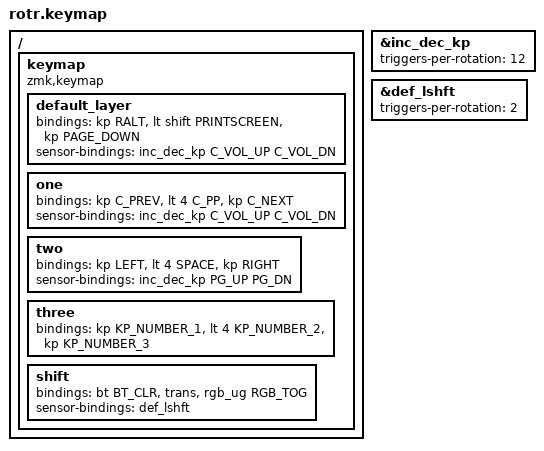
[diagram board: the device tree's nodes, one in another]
#include <behaviors.dtsi>
#include <dt-bindings/zmk/keys.h>
#include <dt-bindings/zmk/rgb.h>
#include <dt-bindings/zmk/bt.h>

&inc_dec_kp {
	triggers-per-rotation = <12>;
};
&def_lshft {
	triggers-per-rotation = <2>;
};

/ {
	keymap {
		compatible = "zmk,keymap";

		default_layer {
			//FUNCTION MACROS
			bindings = <&kp RALT &lt shift PRINTSCREEN &kp PAGE_DOWN>;
			sensor-bindings = <&inc_dec_kp C_VOL_UP C_VOL_DN>;
		};
		one {
			//PREV | PLAY/PAUSE | NEXT
			bindings = <&kp C_PREV &lt 4 C_PP &kp C_NEXT>;
			sensor-bindings = <&inc_dec_kp C_VOL_UP C_VOL_DN>;
		};
		two {
			//PREV | PLAY/PAUSE | NEXT
			bindings = <&kp LEFT &lt 4 SPACE &kp RIGHT>;
			sensor-bindings = <&inc_dec_kp PG_UP PG_DN>;
		};
		three {
			//OSU
			bindings = <&kp KP_NUMBER_1 &lt 4 KP_NUMBER_2 &kp KP_NUMBER_3>;
		};
		shift {
			//PREV | PLAY/PAUSE | NEXT
			bindings = <&bt BT_CLR &trans &rgb_ug RGB_TOG>;
			sensor-bindings = <&def_lshft>;
		};
	};
};
